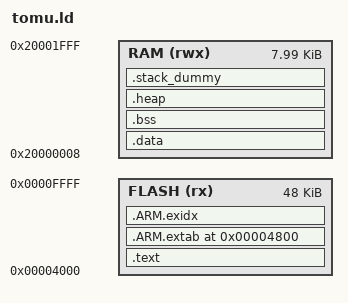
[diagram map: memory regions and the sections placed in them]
/* Linker script for Silicon Labs EFM32HG devices                      */
/*                                                                     */
/* This file is subject to the license terms as defined in ARM's       */
/* CMSIS END USER LICENSE AGREEMENT.pdf, governing the use of          */
/* Example Code.                                                       */
/*                                                                     */
/* Copyright 2016 Silicon Laboratories, Inc. http://www.silabs.com     */
/*                                                                     */
/* Version 5.0.0 */
/*                                                                     */

MEMORY
{
  FLASH (rx) : ORIGIN = 0x00004000, LENGTH = 0xC000
  RAM (rwx)  : ORIGIN = 0x20000000 + 8, LENGTH = 0x2000 - 8
}

ENTRY(Reset_Handler)

SECTIONS
{
  .text :
  {
    KEEP(*(.vectors))
    . = ORIGIN(FLASH) + 0x94;
    KEEP(*(.toboot_header))

    *(.text*)

    KEEP(*(.init))
    KEEP(*(.fini))

    /* .ctors */
    *crtbegin.o(.ctors)
    *crtbegin?.o(.ctors)
    *(EXCLUDE_FILE(*crtend?.o *crtend.o) .ctors)
    *(SORT(.ctors.*))
    *(.ctors)

    /* .dtors */
    *crtbegin.o(.dtors)
    *crtbegin?.o(.dtors)
    *(EXCLUDE_FILE(*crtend?.o *crtend.o) .dtors)
    *(SORT(.dtors.*))
    *(.dtors)

    *(.rodata*)

    KEEP(*(.eh_frame*))
  } > FLASH

  . = 0x4400;
  secure_data1 = .;
  . = 0x4800;
  secure_data2 = .;

  .ARM.extab :
  {
    *(.ARM.extab* .gnu.linkonce.armextab.*)
  } > FLASH

  __exidx_start = .;
  .ARM.exidx :
  {
    *(.ARM.exidx* .gnu.linkonce.armexidx.*)
  } > FLASH
  __exidx_end = .;

  __etext = .;

  toboot_runtime = ORIGIN(RAM) - 8;

  .data : AT (__etext)
  {
    __data_start__ = .;
    *(vtable)
    *(.data*)
    . = ALIGN (4);
    *(.ram)

    . = ALIGN(4);
    /* preinit data */
    PROVIDE_HIDDEN (__preinit_array_start = .);
    KEEP(*(.preinit_array))
    PROVIDE_HIDDEN (__preinit_array_end = .);

    . = ALIGN(4);
    /* init data */
    PROVIDE_HIDDEN (__init_array_start = .);
    KEEP(*(SORT(.init_array.*)))
    KEEP(*(.init_array))
    PROVIDE_HIDDEN (__init_array_end = .);

    . = ALIGN(4);
    /* finit data */
    PROVIDE_HIDDEN (__fini_array_start = .);
    KEEP(*(SORT(.fini_array.*)))
    KEEP(*(.fini_array))
    PROVIDE_HIDDEN (__fini_array_end = .);

    KEEP(*(.jcr*))
    . = ALIGN(4);
    /* All data end */
    __data_end__ = .;

  } > RAM

  .bss :
  {
    . = ALIGN(4);
    __bss_start__ = .;
    *(.bss*)
    *(COMMON)
    . = ALIGN(4);
    __bss_end__ = .;
  } > RAM

  .heap (COPY):
  {
    __HeapBase = .;
    __end__ = .;
    end = __end__;
    _end = __end__;
    KEEP(*(.heap*))
    __HeapLimit = .;
  } > RAM

  /* .stack_dummy section doesn't contains any symbols. It is only
   * used for linker to calculate size of stack sections, and assign
   * values to stack symbols later */
  .stack_dummy (COPY):
  {
    KEEP(*(.stack*))
  } > RAM

  /* Set stack top to end of RAM, and stack limit move down by
   * size of stack_dummy section */
  __StackTop = ORIGIN(RAM) + LENGTH(RAM);
  __StackLimit = __StackTop - SIZEOF(.stack_dummy);
  PROVIDE(__stack = __StackTop);

  /* Check if data + heap + stack exceeds RAM limit */
  ASSERT(__StackLimit >= __HeapLimit, "region RAM overflowed with stack")

  /* Check if FLASH usage exceeds FLASH size */
  ASSERT( LENGTH(FLASH) >= (__etext + SIZEOF(.data)), "FLASH memory overflowed !")
}
